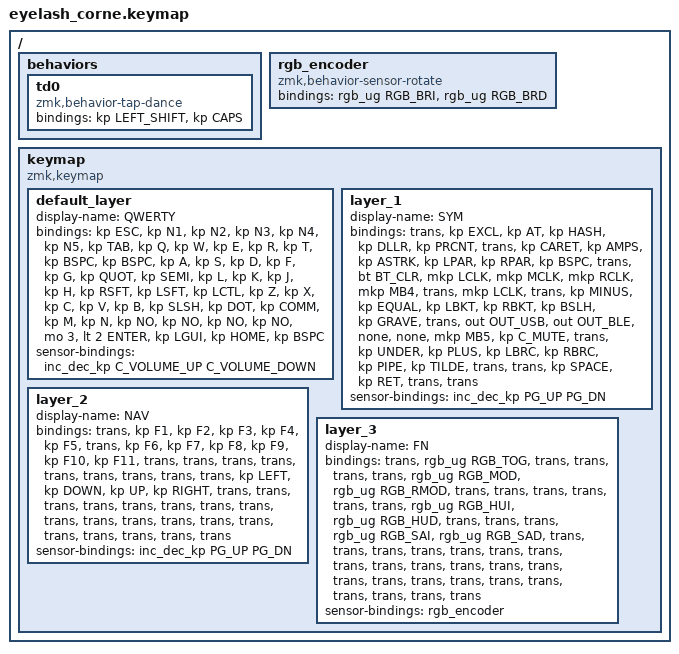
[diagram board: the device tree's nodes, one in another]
// Include necessary behavior and keycode definitions
#include <behaviors.dtsi>
#include <dt-bindings/zmk/bt.h>
#include <dt-bindings/zmk/keys.h>
#include <dt-bindings/zmk/mouse.h>
#include <dt-bindings/zmk/outputs.h>
#include <dt-bindings/zmk/rgb.h>

/ {
    // Define custom behaviors that can be referenced in the keymap
    behaviors {
        // Tap Dance behavior: When tapped, sends LEFT_SHIFT; when held, sends CAPS.
        td0: td0 {
            compatible = "zmk,behavior-tap-dance";
            #binding-cells = <0>;
            bindings = <&kp LEFT_SHIFT>, <&kp CAPS>;
        };
    };

    // Define a behavior for the RGB encoder (used to adjust brightness and speed)
    rgb_encoder: rgb_encoder {
        compatible = "zmk,behavior-sensor-rotate";
        #sensor-binding-cells = <0>;
        bindings = <&rgb_ug RGB_BRI>, <&rgb_ug RGB_BRD>;
    };

    // The keymap node: contains all layers and sensor bindings for the keyboard
    keymap {
        compatible = "zmk,keymap";

        // -----------------------
        // Default (Base) Layer: QWERTY layout
        // -----------------------
        default_layer {
            display-name = "QWERTY";

            bindings = <
                // First row: ESC, 1, 2, 3, 4, 5, TAB, Q, W, E, R, T, BSPC
                &kp ESC    &kp N1    &kp N2    &kp N3    &kp N4    &kp N5      
                          &kp TAB    &kp Q     &kp W     &kp E     &kp R     &kp T     &kp BSPC

                // Second row: BSPC, A, S, D, F, G, QUOT, SEMI, L, K, J, H, RSFT
                &kp BSPC   &kp A     &kp S     &kp D     &kp F     &kp G      
                          &kp QUOT   &kp SEMI  &kp L     &kp K     &kp J     &kp H     &kp RSFT

                // Third row: LSFT, LCTL, Z, X, C, V, B, SLSH, DOT, COMM, M, N, NO, NO
                &kp LSFT   &kp LCTL  &kp Z     &kp X     &kp C     &kp V     &kp B
                          &kp SLSH   &kp DOT   &kp COMM  &kp M     &kp N     &kp NO    &kp NO

                // Bottom row: NO, NO, MO3, LT2 ENTER, LGUI, HOME, BSPC
                             &kp NO   &kp NO   &mo 3     &lt 2 ENTER                                          &kp LGUI  &kp HOME  &kp BSPC
            >;

            sensor-bindings = <&inc_dec_kp C_VOLUME_UP C_VOLUME_DOWN>;
        };

        // -----------------------
        // Layer 1: Symbols and special characters (matching Iris layer 1)
        // -----------------------
        layer_1 {
            display-name = "SYM";
            bindings = <
                // First row: Transparent, EXCL, AT, HASH, DLLR, PRCNT, Transparent, CARET, AMPS, ASTRK, LPAR, RPAR, BSPC
                &trans  &kp EXCL      &kp AT        &kp HASH   &kp DLLR   &kp PRCNT                       
                          &trans            &kp CARET  &kp AMPS   &kp ASTRK  &kp LPAR  &kp RPAR  &kp BSPC

                // Second row: Transparent, BT clear, Left Click (&mkp LCLK), Middle Click (&mkp MCLK), Right Click (&mkp RCLK),
                // &mkp MB4, Transparent, Left Click, Transparent, MINUS, EQUAL, LBKT, RBKT, BSLH, GRAVE
                &trans  &bt BT_CLR    &mkp LCLK     &mkp MCLK  &mkp RCLK  &mkp MB4                
                          &trans  &mkp LCLK  &trans  &kp MINUS  &kp EQUAL  &kp LBKT   &kp RBKT  &kp BSLH  &kp GRAVE

                // Third row: Transparent, OUT_USB, OUT_BLE, none, none, &mkp MB5, C_MUTE, Transparent, UNDER, PLUS, LBRC, RBRC, PIPE, TILDE
                &trans  &out OUT_USB  &out OUT_BLE  &none      &none      &mkp MB5  
                          &kp C_MUTE            &trans            &kp UNDER  &kp PLUS   &kp LBRC   &kp RBRC  &kp PIPE  &kp TILDE

                // Bottom row: Two Transparent entries, SPACE, then RET, Transparent, Transparent
                                    &trans     &trans     &kp SPACE                                         &kp RET    &trans     &trans
            >;

            sensor-bindings = <&inc_dec_kp PG_UP PG_DN>;
        };

        // -----------------------
        // Layer 2: Arrow keys and navigation (matching Iris layer 2)
        // -----------------------
        layer_2 {
            display-name = "NAV";
            bindings = <
                // First row: Transparent, F1, F2, F3, F4, F5, Transparent, F6, F7, F8, F9, F10, F11
                &trans  &kp F1      &kp F2      &kp F3       &kp F4     &kp F5                         
                          &trans            &kp F6       &kp F7     &kp F8       &kp F9      &kp F10          &kp F11

                // Second row: Transparent, Transparent, Transparent, Transparent, Transparent, Transparent,
                // Transparent, Transparent, Transparent, LEFT, DOWN, UP, RIGHT
                &trans  &trans      &trans      &trans       &trans     &trans               
                          &trans    &trans      &trans       &kp LEFT   &kp DOWN   &kp UP    &kp RIGHT

                // Third row: Transparent, Transparent, Transparent, Transparent, Transparent, Transparent,
                // Transparent, Transparent, Transparent, Transparent, Transparent, Transparent, Transparent
                &trans  &trans      &trans      &trans       &trans     &trans
                          &trans    &trans      &trans       &trans     &trans     &trans    &trans

                // Bottom row: Three Transparent entries
                                &trans      &trans      &trans                                           &trans       &trans     &trans
            >;

            sensor-bindings = <&inc_dec_kp PG_UP PG_DN>;
        };

        // -----------------------
        // Layer 3: Function and RGB controls (matching Iris layer 3)
        // -----------------------
        layer_3 {
            display-name = "FN";
            bindings = <
                // First row: Transparent, RGB_TOG, Transparent, Transparent, Transparent, Transparent,
                // RGB_MOD, RGB_RMOD, Transparent, Transparent, Transparent, Transparent, Transparent
                &trans  &rgb_ug RGB_TOG  &trans      &trans       &trans     &trans                         
                          &rgb_ug RGB_MOD  &rgb_ug RGB_RMOD  &trans     &trans       &trans      &trans          &trans

                // Second row: Transparent, RGB_HUI, RGB_HUD, Transparent, Transparent, Transparent,
                // RGB_SAI, RGB_SAD, Transparent, Transparent, Transparent, Transparent, Transparent
                &trans  &rgb_ug RGB_HUI  &rgb_ug RGB_HUD  &trans       &trans     &trans               
                          &rgb_ug RGB_SAI  &rgb_ug RGB_SAD  &trans       &trans     &trans    &trans

                // Third row: Transparent, Transparent, Transparent, Transparent, Transparent, Transparent,
                // Transparent, Transparent, Transparent, Transparent, Transparent, Transparent, Transparent
                &trans  &trans      &trans      &trans       &trans     &trans
                          &trans    &trans      &trans       &trans     &trans     &trans    &trans

                // Bottom row: Three Transparent entries
                                &trans      &trans      &trans                                           &trans       &trans     &trans
            >;

            sensor-bindings = <&rgb_encoder>;
        };
    };
};
